AUTOSAR XML (schema 3.2.1)
package /TERootContainer
  8 x composition type:
    WindowTemperatureSystem
      provide port sense_frost: provided-interface=frost
      provide port sense_noFrost: provided-interface=noFrost
      component WindShieldTemperatureControl: type=WindShieldTemperatureControl
      component WindShieldtemperatureSensor: type=WindShieldtemperatureSensor
      connect WindShieldtemperatureSensor.sense_windShieldTemperature -> WindShieldTemperatureControl.sense_windShieldTemperature
      delegate WindShieldTemperatureControl.no_frost_detected <-> outer port sense_noFrost
      delegate WindShieldTemperatureControl.frost_detected <-> outer port sense_frost
    Power_Window
      8 x require port:
        PW_cls_unlock: required-interface=cls_unlock
        PW_cls_lock: required-interface=cls_lock
        PW_fp_off: required-interface=fp_off
        PW_pw_pos_dn: required-interface=pw_pos_dn
        PW_fp_on: required-interface=fp_on
        PW_pw_pos_up: required-interface=pw_pos_up
        PW_pw_but_up: required-interface=pw_but_up
        PW_pw_but_dn: required-interface=pw_but_dn
      5 x provide port:
        PW_pw_auto_mv_stop: provided-interface=pw_auto_mv_stop
        PW_pw_auto_mv_up: provided-interface=pw_auto_mv_up
        PW_pw_auto_mv_dn: provided-interface=pw_auto_mv_dn
        PW_pw_mv_dn: provided-interface=pw_mv_dn
        PW_pw_mv_up: provided-interface=pw_mv_up
      component ManPW: type=ManPW
      component AutoPW: type=AutoPW
      delegate AutoPW.pw_auto_mv_stop <-> outer port PW_pw_auto_mv_stop
      delegate AutoPW.pw_auto_mv_up <-> outer port PW_pw_auto_mv_up
      delegate AutoPW.pw_auto_mv_dn <-> outer port PW_pw_auto_mv_dn
      delegate ManPW.pw_mv_dn <-> outer port PW_pw_mv_dn
      delegate ManPW.pw_mv_up <-> outer port PW_pw_mv_up
      delegate AutoPW.AUtoPW_cls_unlock <-> outer port PW_cls_unlock
      delegate AutoPW.AutoPW_cls_lock <-> outer port PW_cls_lock
      delegate AutoPW.AutoPW_fp_off <-> outer port PW_fp_off
      delegate AutoPW.AutoPW_fp_on <-> outer port PW_fp_on
      delegate AutoPW.AutoPW_pw_but_dn <-> outer port PW_pw_pos_dn
      delegate AutoPW.AutpPW_pw_but_up <-> outer port PW_pw_pos_up
      delegate AutoPW.AutoPW_pw_pos_up <-> outer port PW_pw_but_up
      delegate AutoPW.AutoPW_pw_pos_dn <-> outer port PW_pw_but_dn
      delegate ManPW.ManPW_cls_unlock <-> outer port PW_cls_unlock
      delegate ManPW.ManPW_cls_lock <-> outer port PW_cls_lock
      delegate ManPW.ManPW_fp_off <-> outer port PW_fp_off
      delegate ManPW.ManPW_fp_on <-> outer port PW_fp_on
      delegate ManPW.ManPW_pw_but_dn <-> outer port PW_pw_pos_dn
      delegate ManPW.ManPW_pw_but_up <-> outer port PW_pw_pos_up
      delegate ManPW.ManPW_pw_pos_up <-> outer port PW_pw_but_up
      delegate ManPW.ManPW_pw_pos_dn <-> outer port PW_pw_but_dn
    WindowHeaterSystem
      require port sense_frost: required-interface=frost
      require port sense_noFrost: required-interface=noFrost
      component WindowHeatableController: type=WindowHeatableController
      component LED_HeatableWindow: type=LED_HeatableWindow
      component WindowHeater: type=WindowHeater
      connect WindowHeatableController.LED_HW_off -> LED_HeatableWindow.lED_HW_off
      connect WindowHeatableController.LED_HW_on -> LED_HeatableWindow.LED_HW_on
      connect WindowHeatableController.WH_off -> WindowHeater.Wh_off
      connect WindowHeatableController.Wh_on -> WindowHeater.WH_on
      delegate WindowHeatableController.sense_frost <-> outer port WindowHeaterSystem/sense_frost
      delegate WindowHeatableController.sense_noFrost <-> outer port WindowHeaterSystem/sense_noFrost
    ManPW
      8 x require port:
        ManPW_cls_unlock: required-interface=cls_unlock
        ManPW_cls_lock: required-interface=cls_lock
        ManPW_fp_off: required-interface=fp_off
        ManPW_fp_on: required-interface=fp_on
        ManPW_pw_pos_dn: required-interface=pw_but_dn
        ManPW_pw_pos_up: required-interface=pw_but_up
        ManPW_pw_but_up: required-interface=pw_pos_up
        ManPW_pw_but_dn: required-interface=pw_pos_dn
      provide port pw_mv_dn: provided-interface=pw_mv_dn
      provide port pw_mv_up: provided-interface=pw_mv_up
    AutomaticSeatadjustement
      require port rckc_keyID: required-interface=rckc_keyId
      9 x component:
        SeatPositioncontroller: type=SeatPositioncontroller
        WheelPosMotor: type=WheelPosMotor
        SeatForwardMotor: type=SeatForwardMotor
        SeatHeigthMotor: type=SeatHeigthMotor
        BackrestMotor: type=BackrestMotor
        WheelPosSensor: type=WheelPossensor
        SeatForwardPosSensor: type=SeatForwardPosSensor
        SeatHeigthSensor: type=SeatHeigthSensor
        BackrestPositionSensor: type=BackrestPositionSensor
      connect SeatPositioncontroller.mv_wheel_down -> WheelPosMotor.mv_wheel_down
      connect SeatPositioncontroller.mv_wheel_up -> WheelPosMotor.mv_wheel_up
      connect SeatPositioncontroller.mv_wheel_forward -> WheelPosMotor.mv_wheel_forward
      connect SeatPositioncontroller.mv_wheel_backward -> WheelPosMotor.mv_wheel_backward
      connect SeatPositioncontroller.mv_seat_backward -> SeatForwardMotor.mv_seat_backward
      connect SeatPositioncontroller.mv_seat_forward -> SeatForwardMotor.mv_seat_forward
      connect SeatPositioncontroller.mv_seat_down -> SeatHeigthMotor.mv_seat_down
      connect SeatPositioncontroller.mv_seat_up -> SeatHeigthMotor.mv_seat_up
      connect SeatPositioncontroller.mv_backrest_down -> BackrestMotor.mv_backrest_down
      connect SeatPositioncontroller.mv_backrest_up -> BackrestMotor.mv_backrest_up
      connect WheelPosSensor.wheelPos -> SeatPositioncontroller.wheelPos
      connect SeatForwardPosSensor.seatForwardPos -> SeatPositioncontroller.seatForwardPos
      connect SeatHeigthSensor.seatHeight -> SeatPositioncontroller.seatHeight
      connect BackrestPositionSensor.backrestPos -> SeatPositioncontroller.backrestPos
      delegate SeatPositioncontroller.rckc_keyID <-> outer port AutomaticSeatadjustement/rckc_keyID
    HL_System
      9 x require port:
        car_motor_off: required-interface=car_motor_off
        car_motor_on: required-interface=car_motor_on
        car_drives: required-interface=car_drives
        turn_HL_auto: required-interface=turn_HL_auto
        turn_HL_off: required-interface=turn_HL_off
        turn_HL_on: required-interface=turn_HL_on
        turn_HB_auto: required-interface=turn_HB_auto
        turn_HB_off: required-interface=turn_HB_off
        turn_HB_on: required-interface=turn_HB_on
      8 x component:
        HL_Controller: type=HL_Controller
        LightSensorController: type=LightSensorController
        HighBeam: type=HighBeam
        LowBeam: type=LowBeam
        DayTimeRunningLights: type=DayTimeRunningLights
        ParkingLights: type=ParkingLights
        ApproachingVehilceSensor: type=ApproachingVehilceSensor
        NatLightSensor: type=NatLightSensor
      connect HL_Controller.HB_off -> HighBeam.HB_off
      connect HL_Controller.HB_on -> HighBeam.HB_on
      connect HL_Controller.LB_off -> LowBeam.LB_off
      connect HL_Controller.LB_on -> LowBeam.LB_on
      connect HL_Controller.DRL_off -> DayTimeRunningLights.DRL_off
      connect HL_Controller.DRL_on -> DayTimeRunningLights.DRL_on
      connect HL_Controller.PL_off -> ParkingLights.PL_off
      connect HL_Controller.PL_on -> ParkingLights.PL_on
      connect HL_Controller.PL_on -> ParkingLights.PL_on
      connect LightSensorController.not_dark -> HL_Controller.not_dark
      connect LightSensorController.dark -> HL_Controller.dark
      connect NatLightSensor.LightingCondition -> LightSensorController.LightingCondition
      connect ApproachingVehilceSensor.AV_detected -> HL_Controller.AV_detected
      connect ApproachingVehilceSensor.no_AV_detected -> HL_Controller.no_AV_detected
      delegate HL_Controller.car_motor_on <-> outer port HL_System/car_motor_on
      delegate HL_Controller.car_motor_off <-> outer port HL_System/car_motor_off
      delegate HL_Controller.car_drives <-> outer port HL_System/car_drives
      delegate HL_Controller.turn_HL_auto <-> outer port HL_System/turn_HL_auto
      delegate HL_Controller.turn_HL_off <-> outer port HL_System/turn_HL_off
      delegate HL_Controller.turn_HL_on <-> outer port HL_System/turn_HL_on
      delegate HL_Controller.turn_HB_auto <-> outer port HL_System/turn_HB_auto
      delegate HL_Controller.turn_HB_off <-> outer port HL_System/turn_HB_off
      delegate HL_Controller.turn_HB_on <-> outer port HL_System/turn_HB_on
    WiperSystem
      10 x require port:
        sense_Frost: required-interface=frost
        sense_noFrost: required-interface=noFrost
        wip_func_auto_but: required-interface=wip_func_auto_but
        wip_func_clean_but: required-interface=wip_func_clean_but
        wip_func_disable_but: required-interface=wip_func_disable_but
        wip_func_perm_but: required-interface=wip_func_perm_but
        wip_func_enable_but: required-interface=wip_func_enable_but
        wip_speed_3_but: required-interface=wip_speed_l3_but
        wip_speed_l2_but: required-interface=wip_speed_l2_but
        wip_speed_l1_but: required-interface=wip_speed_l1_but
      6 x provide port:
        ledWiper_on: provided-interface=ledWiper_on
        ledWiper_off: provided-interface=ledWiper_off
        ledFrostProtecction_off: provided-interface=ledFrostProtection_off
        ledFrostPRotection_on: provided-interface=ledFrostProtection_on
        ledClean_off: provided-interface=ledClean_off
        ledClean_on: provided-interface=ledClean_on
      9 x component:
        ScreenWashController: type=ScreenWashController
        RainSensorController: type=RainSensorController
        WiperController: type=WiperController
        ScreenWashNozzle: type=ScreenWashNozzle
        HighQualityWiper: type=HighQualityWiper
        LowQualityWiper: type=LowQualityWiper
        HighQualityRainSensor: type=HighQualityRainSensor
        LowQualityRainSensor: type=LowQualityRainSensor
        ScreenWashSensor: type=ScreenWashSensor
      connect RainSensorController.rainSensor_WipeFast -> WiperController.rainSensor_WipeFast
      connect RainSensorController.rainSensor_WipeSlow -> WiperController.rainSensor_WipeSlow
      connect RainSensorController.rainSensor_WiperOff -> WiperController.rainSensor_WiperOff
      connect HighQualityRainSensor.sense_heavyRainDetected -> RainSensorController.sense_heavyRainDetected
      connect HighQualityRainSensor.sense_littleRainDetected -> RainSensorController.sense_littleRainDetected
      connect HighQualityRainSensor.sense_noRain -> RainSensorController.sense_noRain
      connect LowQualityRainSensor.sense_rainDetected -> RainSensorController.sense_rainDetected
      connect LowQualityRainSensor.sense_noRain -> RainSensorController.sense_noRain
      connect ScreenWashController.screenWashRefilled -> WiperController.screenWashRefilled
      connect ScreenWashController.screenWashLow -> WiperController.screenWashLow
      connect ScreenWashController.useScreenWash -> WiperController.useScreenWash_1
      connect ScreenWashSensor.sense_screenWashFill -> ScreenWashController.sense_screenWashFill
      connect WiperController.useScreenWash -> ScreenWashNozzle.useScreenWash
      connect WiperController.wipe_fast_speed -> HighQualityWiper.wipe_fast
      connect WiperController.wipe_medium_speed -> HighQualityWiper.wipe_medium
      connect WiperController.wipe_slow_speed -> HighQualityWiper.wipe_slow
      connect WiperController.wipe_clean -> HighQualityWiper.wipe_clean
      connect WiperController.wipe_clean -> LowQualityWiper.wipe_clean
      connect WiperController.wipe_slow_speed -> LowQualityWiper.wipe_slow
      delegate WiperController.autoWiping_off <-> outer port ledWiper_off
      delegate WiperController.autoWiping_on <-> outer port ledWiper_on
      delegate WiperController.ledFrostProtection_off <-> outer port ledFrostProtecction_off
      delegate WiperController.ledFrostProtection_on <-> outer port ledFrostPRotection_on
      delegate WiperController.ledClean_off <-> outer port WiperSystem/ledClean_off
      delegate WiperController.ledClean_on <-> outer port WiperSystem/ledClean_on
      delegate WiperController.wip_speed_l3_but <-> outer port wip_speed_3_but
      delegate WiperController.wip_speed_l2_but <-> outer port WiperSystem/wip_speed_l2_but
      delegate WiperController.frost_detected <-> outer port sense_Frost
      delegate WiperController.no_frost_detected <-> outer port WiperSystem/sense_noFrost
      delegate WiperController.wip_func_auto_but <-> outer port WiperSystem/wip_func_auto_but
      delegate ScreenWashController.wip_func_clean_but <-> outer port WiperSystem/wip_func_clean_but
      delegate WiperController.wip_func_enable_but <-> outer port WiperSystem/wip_func_enable_but
      delegate WiperController.wip_speed_l1_but <-> outer port WiperSystem/wip_speed_l1_but
    System_Software_Architecture  # System Software Architecture
      63 x component:
        HL_System: type=HL_System
        WindowHeaterSystem: type=WindowHeaterSystem
        WindowTemperatureSystem: type=WindowTemperatureSystem
        AutomaticSeatadjustement: type=AutomaticSeatadjustement
        WiperSystem: type=WiperSystem
        Power_Window: type=Power_Window
        LED_AlarmSystemInteriorMonit: type=LED_AlarmSystemInteriorMonit  # LED_AlarmSystemInteriorMonitoring
        LED_AlarmSystemAlarm: type=LED_AlarmSystemAlarm
        LED_AlarmSystemAlarmDetected: type=LED_AlarmSystemAlarmDetected
        LED_AlaramSystemActive: type=LED_AlaramSystemActive
        LED_CentralLockingSystem: type=LED_CentralLockingSystem
        LED_FingerProtection: type=LED_FingerProtection
        LED_ExteriorMirrorHeating: type=LED_ExteriorMirrorHeating
        LED_ExteriorMirrorBottom: type=LED_ExteriorMirrorBottom
        LED_ExteriorMirrorRight: type=LED_ExteriorMirrorRight
        LED_ExteriorMirrorLeft: type=LED_ExteriorMirrorLeft
        LED_ExteriorMirrorTop: type=LED_ExteriorMirrorTop
        LED_AutomaticPowerWindow: type=LED_AutomaticPowerWindow
        LED_ManualPowerWindow: type=LED_ManualPowerWindow
        HumanMachineInterface: type=HumanMachineInterface
        CentralLockingSystem: type=CentralLockingSystem
        RemoteControlKeyController: type=RemoteControlKeyController
        AlarmSystem: type=AlarmSystem
        FingerProtection: type=FingerProtection
        ExteriorMirror: type=ExteriorMirror
        HeadLightSwitch: type=HeadLightSwitch
        HighBeamSwitch: type=HighBeamSwitch
        LEDFrostProtection: type=LEDFrostProtection
        LEDClean: type=LEDClean
        LEDWiper: type=LEDWiper
        Wip_Speed_Panel: type=Wip_Speed_Panel
        Wip_Function_Panel: type=Wip_Function_Panel
        PW_Remote_Control: type=PW_Remote_Control
        Remote_Cotroll_Key: type=Remote_Cotroll_Key
        PW_Button_DN: type=PW_Button_DN
        PW_Button_UP: type=PW_Button_UP
        Alarm_System_Control: type=Alarm_System_Control
        EM_Button: type=EM_Button
        Alarm_Sensor: type=Alarm_Sensor
        LED_ASIM: type=LED_ASIM
        LED_ASAC: type=LED_ASAC
        LED_ASA: type=LED_ASA
        LED_ASAD: type=LED_ASAD
        LED_PW_CLS_UP: type=LED_PW_CLS_UP
        LED_PW_down: type=LED_PW_down
        LED_PW_UP: type=LED_PW_UP
        LED_Heating: type=LED_Heating
        LED_EM_Left: type=LED_EM_Left
        LED_EM_Right: type=LED_EM_Right
        LED_EM_Top: type=LED_EM_Top
        LED_EM_Bottom: type=LED_EM_Bottom
        EM_Motor: type=EM_Motor
        LED_FP: type=LED_FP
        Heating_timer: type=Heating_timer
        Thermometer: type=Thermometer
        EM_Pos_Sensor: type=EM_Pos_Sensor
        Finger_Sensor_SWA: type=Finger_Sensor_SWA
        PW_pos_Sensor: type=PW_pos_Sensor
        Car_locking_system: type=Car_locking_system
        door_sensor: type=door_sensor
        driving_sensor: type=driving_sensor
        Key_Pos_Sensor: type=Key_Pos_Sensor
        CLS_LED: type=CLS_LED
      connect .sense_frost -> .sense_frost  # Assembly Connector286
      connect .sense_frost -> .sense_Frost  # Assembly Connector285
      connect .sense_noFrost -> .sense_noFrost  # Assembly Connector284
      connect .sense_noFrost -> .sense_noFrost  # Assembly Connector283
      connect .ledWiper_off -> LEDWiper.ledWiper_off  # Assembly Connector234
      connect .ledWiper_on -> LEDWiper.ledWiper_on  # Assembly Connector233
      connect .ledFrostProtecction_off -> LEDFrostProtection.ledFrostProtection_off  # Assembly Connector232
      connect .ledFrostPRotection_on -> LEDFrostProtection.ledFrostProtection_on  # Assembly Connector231
      connect .ledClean_off -> LEDClean.ledClean_off  # Assembly Connector230
      connect .ledClean_on -> LEDClean.ledClean_on  # Assembly Connector229
      connect .PW_pw_mv_dn -> LED_ManualPowerWindow.pw_mv_dn
      connect .PW_pw_mv_up -> LED_ManualPowerWindow.pw_mv_up
      connect .PW_pw_auto_mv_dn -> LED_AutomaticPowerWindow.pw_auto_mv_dn  # PW_to_LED_AutoPW_pw_auto_mv_dn
      connect .PW_pw_auto_mv_up -> LED_AutomaticPowerWindow.pw_auto_mv_up  # PW_to_LED_AutpPW_pw_auto_mv_up
      connect .PW_pw_auto_mv_stop -> LED_AutomaticPowerWindow.pw_auto_mv_stop  # PW_to_LED_AutpPW_pw_auto_mv_stop
      connect driving_sensor.car_drives -> .car_drives  # Assembly Connector367
      connect driving_sensor.car_motor_off -> .car_motor_off  # Assembly Connector366
      connect driving_sensor.car_motor_on -> .car_motor_on  # Assembly Connector365
      connect HumanMachineInterface.turn_HL_auto -> .turn_HL_auto  # Assembly Connector364
      connect HumanMachineInterface.turn_HL_off -> .turn_HL_off  # Assembly Connector363
      connect HumanMachineInterface.turn_HL_on -> .turn_HL_on  # Assembly Connector362
      connect HumanMachineInterface.turn_HB_auto -> .turn_HB_auto  # Assembly Connector361
      connect HumanMachineInterface.turn_HB_off -> .turn_HB_off  # Assembly Connector360
      connect HumanMachineInterface.turn_HB_on -> .turn_HB_on  # Assembly Connector359
      connect RemoteControlKeyController.rckc_keyId -> .rckc_keyID  # Assembly Connector252
      connect HumanMachineInterface.wip_func_auto_but -> .wip_func_auto_but  # Assembly Connector242
      connect HumanMachineInterface.wip_func_disable_but -> .wip_func_disable_but  # Assembly Connector241
      connect HumanMachineInterface.wip_func_perm_but -> .wip_func_perm_but  # Assembly Connector240
      connect HumanMachineInterface.wip_func_enable_but -> .wip_func_enable_but  # Assembly Connector239
      connect HumanMachineInterface.wip_func_clean_but -> .wip_func_clean_but  # Assembly Connector238
      connect HumanMachineInterface.wip_speed_l3_but -> .wip_speed_3_but  # Assembly Connector237
      connect HumanMachineInterface.wip_speed_l2_but -> .wip_speed_l2_but  # Assembly Connector236
      connect HumanMachineInterface.wip_speed_l1_but -> .wip_speed_l1_but  # Assembly Connector235
      connect PW_pos_Sensor.pw_pos_dn -> .PW_pw_pos_dn
      connect PW_pos_Sensor.pw_pos_up -> .PW_pw_pos_up
      connect HumanMachineInterface.pw_but_up -> .PW_pw_but_up
      connect FingerProtection.fp_off -> .PW_fp_off
      connect FingerProtection.fp_on -> .PW_fp_on
      connect CentralLockingSystem.cls_unlock -> .PW_cls_unlock
      connect CentralLockingSystem.cls_lock -> .PW_cls_lock
      connect RemoteControlKeyController.pw_but_dn -> .PW_pw_but_dn
      connect RemoteControlKeyController.pw_but_up -> .PW_pw_but_up
      connect HumanMachineInterface.pw_but_dn -> .PW_pw_but_dn
      connect HeadLightSwitch.HL_auto_but -> HumanMachineInterface.HL_auto_but  # Assembly Connector358
      connect HeadLightSwitch.HL_off_but -> HumanMachineInterface.HL_on_but  # Assembly Connector357
      connect HeadLightSwitch.HL_on_but -> HumanMachineInterface.HL_off_but  # Assembly Connector356
      connect HighBeamSwitch.HB_auto_but -> HumanMachineInterface.HB_auto_but  # Assembly Connector355
      connect HighBeamSwitch.HB_on_but -> HumanMachineInterface.HB_on_but  # Assembly Connector354
      connect HighBeamSwitch.HB_off_but -> HumanMachineInterface.HB_off_but  # Assembly Connector353
      connect Remote_Cotroll_Key.rck_keyId -> RemoteControlKeyController.rck_keyID  # Assembly Connector251
      connect Wip_Function_Panel.wip_auto_but -> HumanMachineInterface.wip_auto_but  # Assembly Connector250
      connect Wip_Function_Panel.wip_clean_but -> HumanMachineInterface.wip_clean_but  # Assembly Connector249
      connect Wip_Function_Panel.wip_perm_but -> HumanMachineInterface.wip_perm_but  # Assembly Connector248
      connect Wip_Function_Panel.wip_disable_but -> HumanMachineInterface.wip_disable_but  # Assembly Connector247
      connect Wip_Function_Panel.wip_enable_but -> HumanMachineInterface.wip_enable_but  # Assembly Connector246
      connect Wip_Speed_Panel.wip_l3_but -> HumanMachineInterface.wip_l3_but  # Assembly Connector245
      connect Wip_Speed_Panel.wip_l2_but -> HumanMachineInterface.wip_l2_but  # Assembly Connector244
      connect Wip_Speed_Panel.wip_l1_but -> HumanMachineInterface.wip_l1_but  # Assembly Connector243
      connect Key_Pos_Sensor.key_pos_unlock -> AlarmSystem.key_pos_unlock  # Key_Pos_Sensor_to_AS_key_pos_unlock
      connect Key_Pos_Sensor.key_pos_lock -> AlarmSystem.key_pos_lock  # Key_pos_Sensor_to_AS_key_pos_lock
      connect RemoteControlKeyController.rck_unlock -> AlarmSystem.rck_unlock
      connect RemoteControlKeyController.rck_lock -> AlarmSystem.rck_lock
      connect RemoteControlKeyController.rck_unlock -> CentralLockingSystem.rck_unlock
      connect RemoteControlKeyController.rck_lock -> CentralLockingSystem.rck_lock
      connect door_sensor.door_open -> CentralLockingSystem.door_open
      connect door_sensor.door_open -> RemoteControlKeyController.door_open  # Door_Sensor_to_RCKC_door_open
      connect LED_AlarmSystemInteriorMonit.led_as_im_alarm_off -> LED_ASIM.led_off
      connect LED_AlarmSystemInteriorMonit.led_as_im_alarm_on -> LED_ASIM.led_on
      connect LED_AlaramSystemActive.led_as_active_off -> LED_ASAC.led_off
      connect LED_AlaramSystemActive.led_as_active_on -> LED_ASAC.led_on
      connect LED_AlarmSystemAlarm.led_as_alarm_off -> LED_ASA.led_off
      connect LED_AlarmSystemAlarm.led_as_alarm_on -> LED_ASA.led_on
      connect LED_AlarmSystemAlarmDetected.led_as_alarm_detected_off -> LED_ASAD.led_off
      connect LED_AlarmSystemAlarmDetected.led_as_alarm_detected_on -> LED_ASAD.led_on
      connect LED_AutomaticPowerWindow.led_pw_dn_off -> LED_PW_down.led_off  # LED_AUTOPW_to_LED_PW_down_off
      connect LED_AutomaticPowerWindow.led_pw_dn_on -> LED_PW_down.led_on
      connect LED_ManualPowerWindow.led_pw_dn_on -> LED_PW_down.led_on
      connect LED_AutomaticPowerWindow.led_pw_cls_up_on -> LED_PW_CLS_UP.led_on  # LED_AUTOPW_to_LED_PW_CLS_UP_on
      connect LED_AutomaticPowerWindow.led_pw_cls_up_off -> LED_PW_CLS_UP.led_off  # LED_AUTOPW_to_LED_PW_CLS_UP_off
      connect LED_ManualPowerWindow.led_pw_dn_off -> LED_PW_down.led_off
      connect LED_ManualPowerWindow.led_pw_up_off -> LED_PW_UP.led_off
      connect LED_ManualPowerWindow.led_pw_up_on -> LED_PW_UP.led_on
      connect LED_AutomaticPowerWindow.led_pw_up_off -> LED_PW_UP.led_off
      connect LED_AutomaticPowerWindow.led_pw_up_on -> LED_PW_UP.led_on
      connect LED_ExteriorMirrorHeating.led_em_heating_off -> LED_Heating.led_off  # LED_EM_Heating_to_LED_Heating_off
      connect LED_ExteriorMirrorHeating.led_em_heating_on -> LED_Heating.led_on  # LED_EM_Heating_to_LED_Heating_on
      connect LED_ExteriorMirrorLeft.led_em_left_off -> LED_EM_Left.led_off  # LED_EM_Left_to_LED_EM_Left_off
      connect LED_ExteriorMirrorLeft.led_em_left_on -> LED_EM_Left.led_on  # LED_EM_Left_to_LED_EM_Left_on
      connect LED_ExteriorMirrorRight.led_em_right_off -> LED_EM_Right.led_off  # LED_EM_Right_to_LED_EM_Right_off
      connect LED_ExteriorMirrorRight.led_em_right_on -> LED_EM_Right.led_on  # LED_EM_Right_to_LED_EM_Right_on
      connect LED_ExteriorMirrorTop.led_em_top_off -> LED_EM_Top.led_off
      connect LED_ExteriorMirrorTop.led_em_top_on -> LED_EM_Top.led_on
      connect LED_ExteriorMirrorBottom.led_em_bottom_off -> LED_EM_Bottom.led_off  # LED_EM_Bottom_to_LED_EM_Bottom_off
      connect LED_ExteriorMirrorBottom.led_em_bottom_on -> LED_EM_Bottom.led_on  # LED_EM_Bottom_to_LED_EM_Bottom_on
      connect LED_FingerProtection.led_fp_off -> LED_FP.led_fp_off  # LED_Fingerprotection_to_LED_FP_off
      connect LED_FingerProtection.led_fp_on -> LED_FP.led_fp_on  # LED_Fingerprotection_to_LED_FP_on
      connect Finger_Sensor_SWA.finger_detected -> FingerProtection.finger_detected  # Finger_Snesor_to_FP_finger_detected
      connect ExteriorMirror.em_mv_down -> EM_Motor.em_mv_down
      connect ExteriorMirror.em_mv_up -> EM_Motor.em_mv_up
      connect ExteriorMirror.em_mv_right -> EM_Motor.em_mv_right
      connect ExteriorMirror.em_mv_left -> EM_Motor.em_mv_left
      connect Heating_timer.heating_time_elapsed -> ExteriorMirror.time_heating_elapsed  # Heating_Timer_to_EM_heating_time_elapsed
      connect Thermometer.em_too_cold -> ExteriorMirror.em_too_cold
      connect EM_Pos_Sensor.em_pos_top -> ExteriorMirror.em_pos_top
      connect EM_Pos_Sensor.em_pos_bottom -> ExteriorMirror.em_pos_bottom  # EM_Pos_Sensor_to_EM_pos_bottom
      connect EM_Pos_Sensor.em_pos_right -> ExteriorMirror.em_pos_right  # EM_Pos_Sensor_to_EM_pos_right
      connect EM_Pos_Sensor.em_pos_left -> ExteriorMirror.em_pos_left
      connect Alarm_Sensor.im_alarm_detected -> AlarmSystem.im_alarm_detected  # Alarm_Sensor_to_Alarm_System_im_alarm_detected
      connect Alarm_Sensor.alarm_detected -> AlarmSystem.as_alarm_detected  # Alarm_Sensor_to_Alarm_System_alarm_detected
      connect Alarm_Sensor.alarm_time_elapsed -> AlarmSystem.time_alarm_elapsed  # Alarm_Sensor_to_Alarm_System_time_alarm_elapsed
      connect Key_Pos_Sensor.key_pos_unlock -> CentralLockingSystem.key_pos_unlock
      connect Key_Pos_Sensor.key_pos_lock -> CentralLockingSystem.key_pos_lock
      connect driving_sensor.car_drives -> CentralLockingSystem.car_drives  # Drinving_Sensor_to_CLS_car_drives
      connect PW_Remote_Control.pw_but_down -> RemoteControlKeyController.pw_rm_dn
      connect PW_Remote_Control.pw_but_up -> RemoteControlKeyController.pw_rm_up
      connect Remote_Cotroll_Key.rck_timer -> RemoteControlKeyController.time_rck_sf_elapsed
      connect Remote_Cotroll_Key.rck_but_unlock -> RemoteControlKeyController.rck_but_unlock
      connect Remote_Cotroll_Key.rck_but_lock -> RemoteControlKeyController.rck_but_lock
      connect PW_Button_DN.pw_but_released -> HumanMachineInterface.release_pw_but_dn
      connect PW_Button_DN.pw_but_pressed -> HumanMachineInterface.pw_but_mv_dn
      connect PW_Button_UP.pw_but_released -> HumanMachineInterface.release_pw_but_up
      connect PW_Button_UP.pw_but_pressed -> HumanMachineInterface.pw_but_mv_up
      connect Alarm_System_Control.confirm_alarm -> HumanMachineInterface.confirm_alarm
      connect Alarm_System_Control.deactivate_as -> HumanMachineInterface.deactivate_as
      connect Alarm_System_Control.activate_as -> HumanMachineInterface.activate_as
      connect EM_Button.em_but_mv_dn -> HumanMachineInterface.em_but_mv_dn
      connect EM_Button.em_but_mv_up -> HumanMachineInterface.em_but_mv_up
      connect EM_Button.em_but_mv_right -> HumanMachineInterface.em_but_mv_right  # EM_Button_to_HMI_but_mv_right
      connect EM_Button.em_but_mv_left -> HumanMachineInterface.em_but_mv_left
      connect CentralLockingSystem.car_unlock -> Car_locking_system.car_unlock
      connect CentralLockingSystem.car_lock -> Car_locking_system.car_lock
      connect LED_CentralLockingSystem.led_cls_off -> CLS_LED.led_cls_off
      connect LED_CentralLockingSystem.led_cls_on -> CLS_LED.led_cls_on
      connect ExteriorMirror.heating_on -> LED_ExteriorMirrorHeating.heating_on
      connect ExteriorMirror.heating_off -> LED_ExteriorMirrorHeating.heating_off
      connect ExteriorMirror.em_pos_hor_left -> LED_ExteriorMirrorLeft.em_pos_hor_left  # EM_to_LED_EML_em_pos_hor_left
      connect ExteriorMirror.em_pos_hor_pend -> LED_ExteriorMirrorLeft.em_pos_hor_pend  # EM_to_LED_EML_em_pos_hor_pend
      connect ExteriorMirror.em_pos_hor_pend -> LED_ExteriorMirrorRight.em_pos_hor_pend  # EM_to_LED_EMR_em_pos_hor_pend
      connect ExteriorMirror.em_pos_hor_right -> LED_ExteriorMirrorRight.em_pos_hor_right  # EM_to_LED_EMR_em_pos_hor_right
      connect ExteriorMirror.em_pos_vert_top -> LED_ExteriorMirrorTop.em_pos_vert_top  # EM_to_LED_EMT_em_pos_vert_top
      connect ExteriorMirror.em_pos_vert_pend -> LED_ExteriorMirrorTop.em_pos_vert_pend  # EM_to_LED_EMT_em_pos_vert_pend
      connect ExteriorMirror.em_pos_vert_pend -> LED_ExteriorMirrorBottom.em_pos_vert_pend  # EM_to_LED_EMB_em_pos_vert_pend
      connect ExteriorMirror.em_pos_vert_bottom -> LED_ExteriorMirrorBottom.em_pos_vert_bottom  # EM_to_LED_EMB_em_pos_vert_bottom
      connect HumanMachineInterface.release_pw_but -> LED_ManualPowerWindow.release_pw_but  # HMI_to_LED_ManPW_release_pw_but
      connect AlarmSystem.as_im_alarm_off -> LED_AlarmSystemInteriorMonit.as_im_alarm_off  # AS_to_LED_ASIM_as_im_alarm_off
      connect AlarmSystem.as_im_alarm_on -> LED_AlarmSystemInteriorMonit.as_im_alarm_on  # AS_to_LED_ASIM_as_im_alarm_on
      connect AlarmSystem.as_active_off -> LED_AlaramSystemActive.as_active_off
      connect AlarmSystem.as_active_on -> LED_AlaramSystemActive.as_active_on
      connect CentralLockingSystem.cls_lock -> LED_AutomaticPowerWindow.cls_lock
      connect CentralLockingSystem.cls_unlock -> LED_AutomaticPowerWindow.cls_unlock
      connect AlarmSystem.as_alarm_off -> LED_AlarmSystemAlarm.as_alarm_off
      connect AlarmSystem.as_alarm_on -> LED_AlarmSystemAlarm.as_alarm_on
      connect AlarmSystem.as_alarm_was_detected -> LED_AlarmSystemAlarmDetected.as_alarm_was_detected  # AS_to_LED_ASAD_as_alarm_was_detected
      connect HumanMachineInterface.as_alarm_was_confirmed -> LED_AlarmSystemAlarmDetected.as_alarm_was_confirmed  # HMI_LED_ASAD_alram_was_confirmed
      connect FingerProtection.fp_off -> LED_FingerProtection.fp_off
      connect FingerProtection.fp_on -> LED_FingerProtection.fp_on
      connect HumanMachineInterface.as_activated -> AlarmSystem.as_activated
      connect HumanMachineInterface.as_deactivated -> AlarmSystem.as_deactivated
      connect CentralLockingSystem.cls_lock -> LED_CentralLockingSystem.cls_lock
      connect CentralLockingSystem.cls_unlock -> LED_CentralLockingSystem.cls_unlock
      connect HumanMachineInterface.pw_but_dn -> FingerProtection.pw_but_dn
      connect HumanMachineInterface.em_but_left -> ExteriorMirror.em_but_left
      connect HumanMachineInterface.em_but_up -> ExteriorMirror.em_but_up
      connect HumanMachineInterface.em_but_dn -> ExteriorMirror.em_but_down
      connect HumanMachineInterface.em_but_right -> ExteriorMirror.em_but_right
package /SystemInformation
  system System_System_Software_Architecture:
    fibex-element=[HL_Controller, WindowHeatableController, WindowTemperatureController, SeatAdjustement, ECU5_Wiper, ECU2_HMI, ECU1_Doorsystem, CLS_ECU4, Alarm_System_ECU3, HighBeam, LowBeam, DaytimeRunningLights, ParkingLights, LED_HeatableWindow, WindowHeater, WheelPosMotor, SeatForwardMotor, SeatHeightMotor, BackrestMotor, ScreenWashNozzle, LowQualityWiper, LED_Wiper, LED_Clean, LED_PW_Up, LED_PW_DN, LED_PW_CLS, LED_Frost, LED_FP, LED_EMT, LED_EMR, LED_EML, LED_EMB, LED_EM_Heating, LED_CLS, LED_ASIM, LED_ASAL, LED_ASAD, LED_ASAC, HighQualityWiper, EM_Motor, Car_Locking_System, ApproachingVehicle_snesor, NatLight_sensor, HeadLightSwitch, HighBeamSwitch, WindShieldTemperatureSensor, WheelPositionSensor, SeatForwardSensor, SeatHeightSensor, BackrestPositionSensor, Wiper_Speed_But, Wiper_Function_But, ScreenWashSensor, LowQualityRainSensor, HighQualityRainSensor, Thermoeter, Remote_Control_Key, RCK_PW_Buttons, PW_Position_Sensor, PW_But_UP, PW_But_DN, Key_Pos_Sensor, Heating_Timer, Finger_Sensor_HW, EM_Pos_Sensor, EM_Button, Driving_Snesor, Door_Sensor, Alarm_System_Control, Alarm_Sensor]
    pnc-vector-length=0
    pnc-vector-offset=0
    mapping Mapping
      sw-impl-mappings:
        28 x swc to impl mapping:
          swcMapping_LED_FingerProtect: component-implementation=Impl_LED_FingerProtection, component=System_Software_Architecture.LED_FingerProtection
          swcMapping_ExteriorMirror: component-implementation=Impl_ExteriorMirror, component=System_Software_Architecture.ExteriorMirror
          swcMapping_LED_ExteriorMirro_4: component-implementation=Impl_LED_ExteriorMirrorTop, component=System_Software_Architecture.LED_ExteriorMirrorTop
          swcMapping_LED_ExteriorMirro: component-implementation=Impl_LED_ExteriorMirrorHeati, component=System_Software_Architecture.LED_ExteriorMirrorHeating
          swcMapping_LED_CentralLockin: component-implementation=Impl_LED_CentralLockingSyste, component=System_Software_Architecture.LED_CentralLockingSystem
          swcMapping_LED_AlaramSystemA: component-implementation=Impl_LED_AlaramSystemActive, component=System_Software_Architecture.LED_AlaramSystemActive
          swcMapping_LightSensorContro: component-implementation=Impl_LightSensorController, component=System_Software_Architecture.HL_System.LightSensorController
          swcMapping_ScreenWashControl: component-implementation=Impl_ScreenWashController, component=System_Software_Architecture.WiperSystem.ScreenWashController
          swcMapping_WindowHeatableCon: component-implementation=Impl_WindowHeatableControlle, component=System_Software_Architecture.WindowHeaterSystem.WindowHeatableController
          swcMapping_HumanMachineInter: component-implementation=Impl_HumanMachineInterface, component=System_Software_Architecture.HumanMachineInterface
          swcMapping_LED_ExteriorMirro_3: component-implementation=Impl_LED_ExteriorMirrorLeft, component=System_Software_Architecture.LED_ExteriorMirrorLeft
          swcMapping_RemoteControlKeyC: component-implementation=Impl_RemoteControlKeyControl, component=System_Software_Architecture.RemoteControlKeyController
          swcMapping_RainSensorControl: component-implementation=Impl_RainSensorController, component=System_Software_Architecture.WiperSystem.RainSensorController
          swcMapping_LED_AlarmSystemAl_1: component-implementation=Impl_LED_AlarmSystemAlarmDet, component=System_Software_Architecture.LED_AlarmSystemAlarmDetected
          swcMapping_LED_AutomaticPowe: component-implementation=Impl_LED_AutomaticPowerWindo, component=System_Software_Architecture.LED_AutomaticPowerWindow
          swcMapping_CentralLockingSys: component-implementation=Impl_CentralLockingSystem, component=System_Software_Architecture.CentralLockingSystem
          swcMapping_WiperController: component-implementation=Impl_WiperController, component=System_Software_Architecture.WiperSystem.WiperController
          swcMapping_AutoPW: component-implementation=Impl_AutoPW, component=System_Software_Architecture.Power_Window.AutoPW
          swcMapping_AlarmSystem: component-implementation=Impl_AlarmSystem, component=System_Software_Architecture.AlarmSystem
          swcMapping_LED_ExteriorMirro_2: component-implementation=Impl_LED_ExteriorMirrorRight, component=System_Software_Architecture.LED_ExteriorMirrorRight
          swcMapping_LED_ExteriorMirro_1: component-implementation=Impl_LED_ExteriorMirrorBotto, component=System_Software_Architecture.LED_ExteriorMirrorBottom
          swcMapping_WindShieldTempera: component-implementation=Impl_WindShieldTemperatureCo, component=System_Software_Architecture.WindowTemperatureSystem.WindShieldTemperatureControl
          swcMapping_SeatPositioncontr: component-implementation=Impl_SeatPositioncontroller, component=System_Software_Architecture.AutomaticSeatadjustement.SeatPositioncontroller
          swcMapping_LED_AlarmSystemAl: component-implementation=Impl_LED_AlarmSystemAlarm, component=System_Software_Architecture.LED_AlarmSystemAlarm
          swcMapping_FingerProtection: component-implementation=Impl_FingerProtection, component=System_Software_Architecture.FingerProtection
          swcMapping_LED_ManualPowerWi: component-implementation=Impl_LED_ManualPowerWindow, component=System_Software_Architecture.LED_ManualPowerWindow
          swcMapping_LED_AlarmSystemIn: component-implementation=Impl_LED_AlarmSystemInterior, component=System_Software_Architecture.LED_AlarmSystemInteriorMonit
          swcMapping_HL_Controller: component-implementation=Impl_HL_Controller, component=System_Software_Architecture.HL_System.HL_Controller
      sw-mappings:
        68 x swc to ecu mapping:
          SeatHeightMotor_FBMapping: component=System_Software_Architecture.AutomaticSeatadjustement.SeatHeigthMotor, ecu-instance=SeatHeightMotor
          ECU5_Wiper_FBMapping: ecu-instance=ECU5_Wiper
            component:
              System_Software_Architecture.WiperSystem.ScreenWashController
              System_Software_Architecture.WiperSystem.WiperController
              System_Software_Architecture.WiperSystem.RainSensorController
          LED_HeatableWindow_FBMapping: component=System_Software_Architecture.WindowHeaterSystem.LED_HeatableWindow, ecu-instance=LED_HeatableWindow
          ApproachingVehicle_snesor_FB: component=System_Software_Architecture.HL_System.ApproachingVehilceSensor, ecu-instance=ApproachingVehicle_snesor
          HighQualityWiper_FBMapping: component=System_Software_Architecture.WiperSystem.HighQualityWiper, ecu-instance=HighQualityWiper
          RCK_PW_Buttons_FBMapping: component=System_Software_Architecture.PW_Remote_Control, ecu-instance=RCK_PW_Buttons
          CLS_ECU4_FBMapping: ecu-instance=CLS_ECU4
            component:
              System_Software_Architecture.RemoteControlKeyController
              System_Software_Architecture.CentralLockingSystem
          ECU1_Doorsystem_FBMapping: ecu-instance=ECU1_Doorsystem
            component:
              System_Software_Architecture.Power_Window.AutoPW
              System_Software_Architecture.ExteriorMirror
              System_Software_Architecture.FingerProtection
              System_Software_Architecture.Power_Window.ManPW
          ECU2_HMI_FBMapping: ecu-instance=ECU2_HMI
            component:
              System_Software_Architecture.LED_ExteriorMirrorTop
              System_Software_Architecture.LED_AlarmSystemAlarm
              System_Software_Architecture.HumanMachineInterface
              System_Software_Architecture.LED_ExteriorMirrorBottom
              System_Software_Architecture.LED_AlaramSystemActive
              System_Software_Architecture.LED_ExteriorMirrorLeft
              System_Software_Architecture.LED_ExteriorMirrorHeating
              System_Software_Architecture.LED_ManualPowerWindow
              System_Software_Architecture.LED_CentralLockingSystem
              System_Software_Architecture.LED_AlarmSystemAlarmDetected
              System_Software_Architecture.LED_ExteriorMirrorRight
              System_Software_Architecture.LED_AlarmSystemInteriorMonit
              System_Software_Architecture.LED_FingerProtection
              System_Software_Architecture.LED_AutomaticPowerWindow
          EM_Pos_Sensor_FBMapping: component=System_Software_Architecture.EM_Pos_Sensor, ecu-instance=EM_Pos_Sensor
          LED_ASIM_FBMapping: component=System_Software_Architecture.LED_ASIM, ecu-instance=LED_ASIM
          ScreenWashSensor_FBMapping: ecu-instance=ScreenWashSensor
            component:
              System_Software_Architecture.WiperSystem.ScreenWashSensor
              System_Software_Architecture.WiperSystem.ScreenWashNozzle
          BackrestPositionSensor_FBMap: component=System_Software_Architecture.AutomaticSeatadjustement.BackrestPositionSensor, ecu-instance=BackrestPositionSensor
          LED_EMR_FBMapping: component=System_Software_Architecture.LED_EM_Right, ecu-instance=LED_EMR
          EM_Motor_FBMapping: component=System_Software_Architecture.EM_Motor, ecu-instance=EM_Motor
          HL_Controller_FBMapping: ecu-instance=HL_Controller
            component:
              System_Software_Architecture.HL_System.LightSensorController
              System_Software_Architecture.HL_System.HL_Controller
          Remote_Control_Key_FBMapping: component=System_Software_Architecture.Remote_Cotroll_Key, ecu-instance=Remote_Control_Key
          LED_Wiper_FBMapping: component=System_Software_Architecture.LEDWiper, ecu-instance=LED_Wiper
          LowBeam_FBMapping: component=System_Software_Architecture.HL_System.LowBeam, ecu-instance=LowBeam
          LED_EMT_FBMapping: component=System_Software_Architecture.LED_EM_Top, ecu-instance=LED_EMT
          WindowTemperatureController_: component=System_Software_Architecture.WindowTemperatureSystem.WindShieldTemperatureControl, ecu-instance=WindowTemperatureController
          Key_Pos_Sensor_FBMapping: component=System_Software_Architecture.Key_Pos_Sensor, ecu-instance=Key_Pos_Sensor
          HighQualityRainSensor_FBMapp: component=System_Software_Architecture.WiperSystem.HighQualityRainSensor, ecu-instance=HighQualityRainSensor
          Heating_Timer_FBMapping: component=System_Software_Architecture.Heating_timer, ecu-instance=Heating_Timer
          SeatForwardMotor_FBMapping: component=System_Software_Architecture.AutomaticSeatadjustement.SeatForwardMotor, ecu-instance=SeatForwardMotor
          DaytimeRunningLights_FBMappi: component=System_Software_Architecture.HL_System.DayTimeRunningLights, ecu-instance=DaytimeRunningLights
          Driving_Snesor_FBMapping: component=System_Software_Architecture.driving_sensor, ecu-instance=Driving_Snesor
          ParkingLights_FBMapping: component=System_Software_Architecture.HL_System.ParkingLights, ecu-instance=ParkingLights
          PW_But_DN_FBMapping: component=System_Software_Architecture.PW_Button_DN, ecu-instance=PW_But_DN
          SeatAdjustement_FBMapping: component=System_Software_Architecture.AutomaticSeatadjustement.SeatPositioncontroller, ecu-instance=SeatAdjustement
          LED_CLS_FBMapping: component=[System_Software_Architecture.LED_PW_CLS_UP, System_Software_Architecture.CLS_LED], ecu-instance=LED_CLS
          LED_FP_FBMapping: component=System_Software_Architecture.LED_FP, ecu-instance=LED_FP
          Door_Sensor_FBMapping: component=System_Software_Architecture.door_sensor, ecu-instance=Door_Sensor
          BackrestMotor_FBMapping: component=System_Software_Architecture.AutomaticSeatadjustement.BackrestMotor, ecu-instance=BackrestMotor
          WheelPosMotor_FBMapping: component=System_Software_Architecture.AutomaticSeatadjustement.WheelPosMotor, ecu-instance=WheelPosMotor
          LowQualityRainSensor_FBMappi: component=System_Software_Architecture.WiperSystem.LowQualityRainSensor, ecu-instance=LowQualityRainSensor
          LED_ASAC_FBMapping: component=System_Software_Architecture.LED_ASAC, ecu-instance=LED_ASAC
          PW_But_UP_FBMapping: component=System_Software_Architecture.PW_Button_UP, ecu-instance=PW_But_UP
          Alarm_System_ECU3_FBMapping: component=System_Software_Architecture.AlarmSystem, ecu-instance=Alarm_System_ECU3
          Finger_Sensor_HW_FBMapping: component=System_Software_Architecture.Finger_Sensor_SWA, ecu-instance=Finger_Sensor_HW
          WindowHeatableController_FBM: component=System_Software_Architecture.WindowHeaterSystem.WindowHeatableController, ecu-instance=WindowHeatableController
          LED_EMB_FBMapping: component=System_Software_Architecture.LED_EM_Bottom, ecu-instance=LED_EMB
          WindShieldTemperatureSensor_: component=System_Software_Architecture.WindowTemperatureSystem.WindShieldtemperatureSensor, ecu-instance=WindShieldTemperatureSensor
          Alarm_Sensor_FBMapping: component=System_Software_Architecture.Alarm_Sensor, ecu-instance=Alarm_Sensor
          NatLight_sensor_FBMapping: component=System_Software_Architecture.HL_System.NatLightSensor, ecu-instance=NatLight_sensor
          HighBeam_FBMapping: component=System_Software_Architecture.HL_System.HighBeam, ecu-instance=HighBeam
          SeatForwardSensor_FBMapping: component=System_Software_Architecture.AutomaticSeatadjustement.SeatForwardPosSensor, ecu-instance=SeatForwardSensor
          LowQualityWiper_FBMapping: component=System_Software_Architecture.WiperSystem.LowQualityWiper, ecu-instance=LowQualityWiper
          WheelPositionSensor_FBMappin: component=System_Software_Architecture.AutomaticSeatadjustement.WheelPosSensor, ecu-instance=WheelPositionSensor
          LED_ASAL_FBMapping: component=System_Software_Architecture.LED_ASA, ecu-instance=LED_ASAL
          Car_Locking_System_FBMapping: component=System_Software_Architecture.Car_locking_system, ecu-instance=Car_Locking_System
          LED_PW_DN_FBMapping: component=System_Software_Architecture.LED_PW_down, ecu-instance=LED_PW_DN
          Wiper_Function_But_FBMapping: component=System_Software_Architecture.Wip_Function_Panel, ecu-instance=Wiper_Function_But
          SeatHeightSensor_FBMapping: component=System_Software_Architecture.AutomaticSeatadjustement.SeatHeigthSensor, ecu-instance=SeatHeightSensor
          Wiper_Speed_But_FBMapping: component=System_Software_Architecture.Wip_Speed_Panel, ecu-instance=Wiper_Speed_But
          PW_Position_Sensor_FBMapping: component=System_Software_Architecture.PW_pos_Sensor, ecu-instance=PW_Position_Sensor
          LED_Clean_FBMapping: component=System_Software_Architecture.LEDClean, ecu-instance=LED_Clean
          LED_EM_Heating_FBMapping: component=System_Software_Architecture.LED_Heating, ecu-instance=LED_EM_Heating
          LED_EML_FBMapping: component=System_Software_Architecture.LED_EM_Left, ecu-instance=LED_EML
          Alarm_System_Control_FBMappi: component=System_Software_Architecture.Alarm_System_Control, ecu-instance=Alarm_System_Control
          WindowHeater_FBMapping: component=System_Software_Architecture.WindowHeaterSystem.WindowHeater, ecu-instance=WindowHeater
          HighBeamSwitch_FBMapping: component=System_Software_Architecture.HighBeamSwitch, ecu-instance=HighBeamSwitch
          EM_Button_FBMapping: component=System_Software_Architecture.EM_Button, ecu-instance=EM_Button
          LED_PW_Up_FBMapping: component=System_Software_Architecture.LED_PW_UP, ecu-instance=LED_PW_Up
          LED_Frost_FBMapping: component=System_Software_Architecture.LEDFrostProtection, ecu-instance=LED_Frost
          Thermoeter_FBMapping: component=System_Software_Architecture.Thermometer, ecu-instance=Thermoeter
          LED_ASAD_FBMapping: component=System_Software_Architecture.LED_ASAD, ecu-instance=LED_ASAD
          HeadLightSwitch_FBMapping: component=System_Software_Architecture.HeadLightSwitch, ecu-instance=HeadLightSwitch
    software composition System_Software_Architecture: software-composition=System_Software_Architecture
package /Software_Types  # Software Types
package /Software_Types/Interface_Types  # Interface Types
package /Software_Types/Interface_Types/Sender__Receiver_Interfaces  # Sender-/Receiver Interfaces
package /Software_Types/Interface_Types/Sender__Receiver_Interfaces/BCS_AutomaticHeadLights/signal_internal
  8 x sender receiver interface:
    not_dark
    dark
    turn_HL_auto
    turn_HL_off
    turn_HL_on
    turn_HB_auto
    turn_HB_on
    turn_HB_off
package /Software_Types/Interface_Types/Sender__Receiver_Interfaces/BCS_AutomaticHeadLights/signal_output
  8 x sender receiver interface:
    HB_off
    HB_on
    LB_off
    LB_on
    DRL_off
    DRL_on
    PL_off
    PL_on
package /Software_Types/Interface_Types/Sender__Receiver_Interfaces/BCS_AutomaticHeadLights/signal_input
  11 x sender receiver interface:
    no_AV_detected
    AV_detected
    LightingCondition
    car_motor_off
    car_motor_on
    HL_auto_but
    HL_off_but
    HL_on_but
    HB_on_but
    HB_auto_but
    HB_off_but
package /Software_Types/Interface_Types/Sender__Receiver_Interfaces/BCS_HeatableWindows/signal_output
  4 x sender receiver interface:
    LED_HW_off
    LED_HW_on
    WH_off
    WH_on
package /Software_Types/Interface_Types/Sender__Receiver_Interfaces/BCS_WindowTemperatur/signal_internal
  sender receiver interface noFrost
  sender receiver interface frost
package /Software_Types/Interface_Types/Sender__Receiver_Interfaces/BCS_WindowTemperatur/signal_input
  sender receiver interface windShieldTemperature
package /Software_Types/Interface_Types/Sender__Receiver_Interfaces/BCS_SeatAdjustement/signal_internal
  sender receiver interface rckc_keyId
package /Software_Types/Interface_Types/Sender__Receiver_Interfaces/BCS_SeatAdjustement/signal_output
  10 x sender receiver interface:
    mv_wheel_forward
    mv_wheel_backward
    mv_wheel_down
    mv_wheel_up
    mv_seat_backward
    mv_seat_forward
    mv_seat_down
    mv_seat_up
    mv_backrest_down
    mv_backrest_up
package /Software_Types/Interface_Types/Sender__Receiver_Interfaces/BCS_SeatAdjustement/signal_input
  5 x sender receiver interface:
    rck_keyId
    wheel_pos
    seat_forward_pos
    seatHeight
    backrestPos
package /Software_Types/Interface_Types/Sender__Receiver_Interfaces/BCS_Wiper/signal_output
  10 x sender receiver interface:
    wipe_clean
    wipe_fast_speed
    wipe_medium_speed
    wipe_slow_speed
    ledWiper_off
    ledWiper_on
    ledFrostProtection_off
    ledFrostProtection_on
    ledClean_off
    ledClean_on
package /Software_Types/Interface_Types/Sender__Receiver_Interfaces/BCS_Wiper/signal_internal
  15 x sender receiver interface:
    useScreenWash
    screenWashRefilled
    screenWashLow
    rainSensor_WipeFast
    rainSensor_WipeSlow
    rainSensor_WiperOff
    clean_screen
    wip_func_auto_but
    wip_func_perm_but
    wip_func_disable_but
    wip_func_enable_but
    wip_func_clean_but
    wip_speed_l3_but
    wip_speed_l2_but
    wip_speed_l1_but
package /Software_Types/Interface_Types/Sender__Receiver_Interfaces/BCS_Wiper/signal_input
  13 x sender receiver interface:
    heavyRain_detected
    littleRain_detected
    rainDetected
    noRain_detected
    screenWashFill
    wip_auto_but
    wip_clean_but
    wip_perm_but
    wip_disable_but
    wip_enable_but
    wip_l3_but
    wip_l2_but
    wip_l1_but
package /Software_Types/Interface_Types/Sender__Receiver_Interfaces/BCS_Basic/signal_output
  34 x sender receiver interface:
    led_pw_up_on
    led_pw_up_off
    led_pw_dn_on
    led_pw_dn_off
    led_pw_cls_up_on
    led_pw_cls_up_off
    led_fp_on
    led_fp_off
    led_em_top_on
    led_em_top_off
    led_em_right_on
    led_em_right_off
    led_em_left_on
    led_em_left_off
    led_em_heating_on
    led_em_heating_off
    led_em_bottom_on
    led_em_bottom_off
    led_cls_on
    led_cls_off
    led_as_im_alarm_on
    led_as_im_alarm_off
    led_as_alarm_on
    led_as_alarm_off
    led_as_alarm_detected_on
    led_as_alarm_detected_off
    led_as_active_on
    led_as_active_off
    em_mv_up
    em_mv_right
    em_mv_left
    em_mv_down
    car_unlock
    car_lock
package /Software_Types/Interface_Types/Sender__Receiver_Interfaces/BCS_Basic/signal_input
  32 x sender receiver interface:
    time_rck_sf_elapsed
    time_heating_elapsed
    time_alarm_elapsed
    release_pw_but_up
    release_pw_but_dn
    rck_but_unlock
    rck_but_lock
    pw_rm_up
    pw_rm_dn
    pw_pos_up
    pw_pos_dn
    pw_but_mv_up
    pw_but_mv_dn
    key_pos_unlock
    key_pos_lock
    im_alarm_detected
    finger_detected
    em_too_cold
    em_pos_top
    em_pos_right
    em_pos_left
    em_pos_bottom
    em_but_mv_up
    em_but_mv_right
    em_but_mv_left
    em_but_mv_dn
    door_open
    deactivate_as
    confirm_alarm
    car_drives
    as_alarm_detected
    activate_as
package /Software_Types/Interface_Types/Sender__Receiver_Interfaces/BCS_Basic/signal_internal
  36 x sender receiver interface:
    release_pw_but
    rck_unlock
    rck_lock
      data rck_lock
    pw_mv_up
    pw_mv_dn
    pw_but_up
    pw_but_dn
    pw_auto_mv_up
    pw_auto_mv_stop
    pw_auto_mv_dn
    heating_on
    heating_off
    fp_on
    fp_off
    em_pos_vert_top
    em_pos_vert_pend
    em_pos_vert_bottom
    em_pos_hor_right
    em_pos_hor_pend
    em_pos_hor_left
    em_but_up
    em_but_right
    em_but_left
    em_but_down
    cls_unlock
    cls_lock
    as_im_alarm_on
    as_im_alarm_off
    as_deactivated
    as_alarm_was_detected
    as_alarm_was_confirmed
    as_alarm_on
    as_alarm_off
    as_active_on
    as_active_off
    as_activated
package /Software_Types/Block_Types  # Block Types
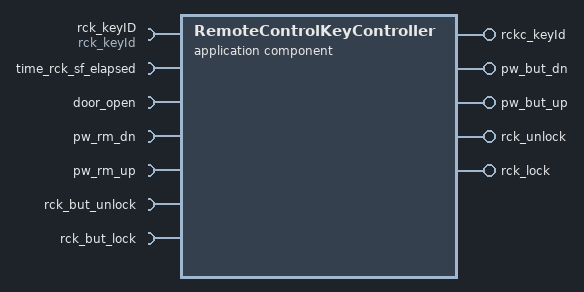
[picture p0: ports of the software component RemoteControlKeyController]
  application software component type RemoteControlKeyController
    7 x require port:
      rck_keyID: required-interface=rck_keyId
      time_rck_sf_elapsed: required-interface=time_rck_sf_elapsed
      door_open: required-interface=door_open
      pw_rm_dn: required-interface=pw_rm_dn
      pw_rm_up: required-interface=pw_rm_up
      rck_but_unlock: required-interface=rck_but_unlock
      rck_but_lock: required-interface=rck_but_lock
    5 x provide port:
      rckc_keyId: provided-interface=rckc_keyId
      pw_but_dn: provided-interface=pw_but_dn
      pw_but_up: provided-interface=pw_but_up
      rck_unlock: provided-interface=rck_unlock
      rck_lock: provided-interface=rck_lock
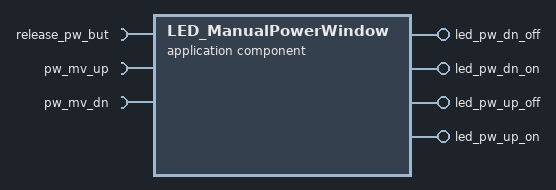
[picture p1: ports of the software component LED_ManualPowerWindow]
  application software component type LED_ManualPowerWindow
    require port release_pw_but: required-interface=release_pw_but
    require port pw_mv_up: required-interface=pw_mv_up
    require port pw_mv_dn: required-interface=pw_mv_dn
    4 x provide port:
      led_pw_dn_off: provided-interface=led_pw_dn_off
      led_pw_dn_on: provided-interface=led_pw_dn_on
      led_pw_up_off: provided-interface=led_pw_up_off
      led_pw_up_on: provided-interface=led_pw_up_on
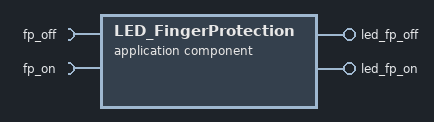
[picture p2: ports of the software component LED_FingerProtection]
  application software component type LED_FingerProtection
    require port fp_off: required-interface=fp_off
    require port fp_on: required-interface=fp_on
    provide port led_fp_off: provided-interface=led_fp_off
    provide port led_fp_on: provided-interface=led_fp_on
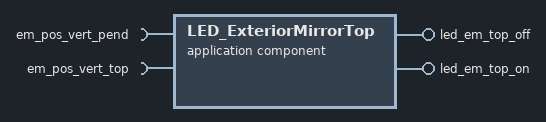
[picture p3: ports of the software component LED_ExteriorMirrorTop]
  application software component type LED_ExteriorMirrorTop
    require port em_pos_vert_pend: required-interface=em_pos_vert_pend
    require port em_pos_vert_top: required-interface=em_pos_vert_top
    provide port led_em_top_off: provided-interface=led_em_top_off
    provide port led_em_top_on: provided-interface=led_em_top_on
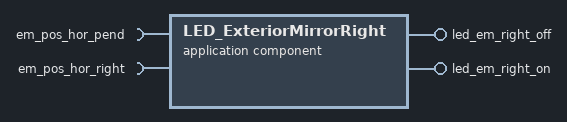
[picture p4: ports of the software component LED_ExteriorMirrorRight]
  application software component type LED_ExteriorMirrorRight
    require port em_pos_hor_pend: required-interface=em_pos_hor_pend
    require port em_pos_hor_right: required-interface=em_pos_hor_right
    provide port led_em_right_off: provided-interface=led_em_right_off
    provide port led_em_right_on: provided-interface=led_em_right_on
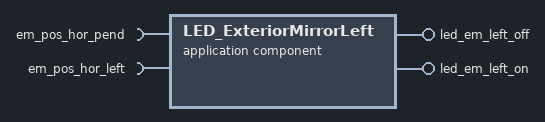
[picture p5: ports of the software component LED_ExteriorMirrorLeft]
  application software component type LED_ExteriorMirrorLeft
    require port em_pos_hor_pend: required-interface=em_pos_hor_pend
    require port em_pos_hor_left: required-interface=em_pos_hor_left
    provide port led_em_left_off: provided-interface=led_em_left_off
    provide port led_em_left_on: provided-interface=led_em_left_on
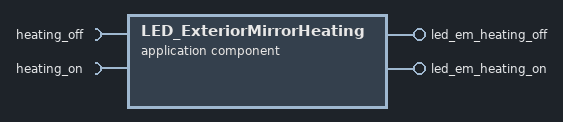
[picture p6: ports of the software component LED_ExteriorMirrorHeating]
  application software component type LED_ExteriorMirrorHeating
    require port heating_off: required-interface=heating_off
    require port heating_on: required-interface=heating_on
    provide port led_em_heating_off: provided-interface=led_em_heating_off
    provide port led_em_heating_on: provided-interface=led_em_heating_on
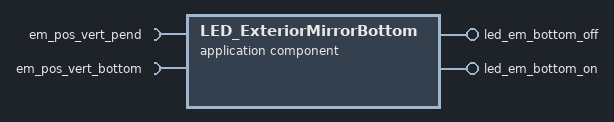
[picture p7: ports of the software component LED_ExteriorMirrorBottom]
  application software component type LED_ExteriorMirrorBottom
    require port em_pos_vert_pend: required-interface=em_pos_vert_pend
    require port em_pos_vert_bottom: required-interface=em_pos_vert_bottom
    provide port led_em_bottom_off: provided-interface=led_em_bottom_off
    provide port led_em_bottom_on: provided-interface=led_em_bottom_on
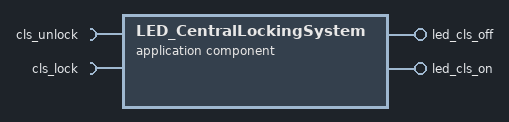
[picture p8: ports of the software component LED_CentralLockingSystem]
  application software component type LED_CentralLockingSystem
    require port cls_unlock: required-interface=cls_unlock
    require port cls_lock: required-interface=cls_lock
    provide port led_cls_off: provided-interface=led_cls_off
    provide port led_cls_on: provided-interface=led_cls_on
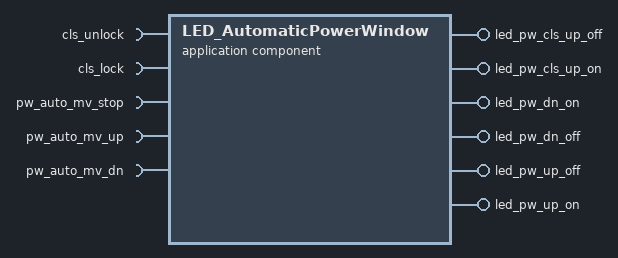
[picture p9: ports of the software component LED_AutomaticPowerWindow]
  application software component type LED_AutomaticPowerWindow
    5 x require port:
      cls_unlock: required-interface=cls_unlock
      cls_lock: required-interface=cls_lock
      pw_auto_mv_stop: required-interface=pw_auto_mv_stop
      pw_auto_mv_up: required-interface=pw_auto_mv_up
      pw_auto_mv_dn: required-interface=pw_auto_mv_dn
    6 x provide port:
      led_pw_cls_up_off: provided-interface=led_pw_cls_up_off
      led_pw_cls_up_on: provided-interface=led_pw_cls_up_on
      led_pw_dn_on: provided-interface=led_pw_dn_on
      led_pw_dn_off: provided-interface=led_pw_dn_off
      led_pw_up_off: provided-interface=led_pw_up_off
      led_pw_up_on: provided-interface=led_pw_up_on
  application software component type LED_AlarmSystemInteriorMonit  # LED_AlarmSystemInteriorMonitoring
    require port as_im_alarm_off: required-interface=as_im_alarm_off
    require port as_im_alarm_on: required-interface=as_im_alarm_on
    provide port led_as_im_alarm_off: provided-interface=led_as_im_alarm_off
    provide port led_as_im_alarm_on: provided-interface=led_as_im_alarm_on
  application software component type LED_AlarmSystemAlarmDetected
    require port as_alarm_was_confirmed: required-interface=as_alarm_was_confirmed
    require port as_alarm_was_detected: required-interface=as_alarm_was_detected
    provide port led_as_alarm_detected_off: provided-interface=led_as_alarm_detected_off
    provide port led_as_alarm_detected_on: provided-interface=led_as_alarm_detected_on
  application software component type LED_AlarmSystemAlarm
    require port as_alarm_off: required-interface=as_alarm_off
    require port as_alarm_on: required-interface=as_alarm_on
    provide port led_as_alarm_off: provided-interface=led_as_alarm_off
    provide port led_as_alarm_on: provided-interface=led_as_alarm_on
  application software component type LED_AlaramSystemActive
    require port as_active_off: required-interface=as_active_off
    require port as_active_on: required-interface=as_active_on
    provide port led_as_active_off: provided-interface=led_as_active_off
    provide port led_as_active_on: provided-interface=led_as_active_on
  application software component type HumanMachineInterface
    25 x require port:
      HL_auto_but: required-interface=HL_auto_but
      HL_on_but: required-interface=HL_off_but
      HL_off_but: required-interface=HL_on_but
      HB_auto_but: required-interface=HB_auto_but
      HB_on_but: required-interface=HB_on_but
      HB_off_but: required-interface=HB_off_but
      wip_auto_but: required-interface=wip_auto_but
      wip_l{1..3}_but: required-interface=wip_l{1..3}_but
      wip_enable_but: required-interface=wip_enable_but
      wip_disable_but: required-interface=wip_disable_but
      wip_perm_but: required-interface=wip_perm_but
      wip_clean_but: required-interface=wip_clean_but
      release_pw_but_up: required-interface=release_pw_but_up
      release_pw_but_dn: required-interface=release_pw_but_dn
      confirm_alarm: required-interface=confirm_alarm
      deactivate_as: required-interface=deactivate_as
      activate_as: required-interface=activate_as
      em_but_mv_dn: required-interface=em_but_mv_dn
      em_but_mv_up: required-interface=em_but_mv_up
      em_but_mv_right: required-interface=em_but_mv_right
      em_but_mv_left: required-interface=em_but_mv_left
      pw_but_mv_up: required-interface=pw_but_mv_up
      pw_but_mv_dn: required-interface=pw_but_mv_dn
    25 x provide port:
      turn_HL_auto: provided-interface=turn_HL_auto
      turn_HL_off: provided-interface=turn_HL_off
      turn_HL_on: provided-interface=turn_HL_on
      turn_HB_auto: provided-interface=turn_HB_auto
      turn_HB_off: provided-interface=turn_HB_off
      turn_HB_on: provided-interface=turn_HB_on
      wip_func_auto_but: provided-interface=wip_func_auto_but
      Sender_Portprototyp146  # Sender Portprototyp146
      wip_func_clean_but: provided-interface=wip_func_clean_but
      wip_speed_l{1..3}_but: provided-interface=wip_speed_l{1..3}_but
      wip_func_enable_but: provided-interface=wip_func_enable_but
      wip_func_perm_but: provided-interface=wip_func_perm_but
      wip_func_disable_but: provided-interface=wip_func_disable_but
      release_pw_but: provided-interface=release_pw_but
      as_alarm_was_confirmed: provided-interface=as_alarm_was_confirmed
      as_deactivated: provided-interface=as_deactivated
      as_activated: provided-interface=as_activated
      em_but_right: provided-interface=em_but_right
      em_but_left: provided-interface=em_but_left
      em_but_up: provided-interface=em_but_up
      em_but_dn: provided-interface=em_but_down
      pw_but_dn: provided-interface=pw_but_dn
      pw_but_up: provided-interface=pw_but_up
  application software component type FingerProtection
    require port pw_but_dn: required-interface=pw_but_dn
    require port finger_detected: required-interface=finger_detected
    provide port fp_off: provided-interface=fp_off
    provide port fp_on: provided-interface=fp_on
  application software component type ExteriorMirror
    10 x require port:
      time_heating_elapsed: required-interface=time_heating_elapsed
      em_too_cold: required-interface=em_too_cold
      em_pos_top: required-interface=em_pos_top
      em_pos_bottom: required-interface=em_pos_bottom
      em_pos_right: required-interface=em_pos_right
      em_pos_left: required-interface=em_pos_left
      em_but_left: required-interface=em_but_left
      em_but_up: required-interface=em_but_up
      em_but_down: required-interface=em_but_down
      em_but_right: required-interface=em_but_right
    12 x provide port:
      em_pos_hor_left: provided-interface=em_pos_hor_left
      em_pos_hor_right: provided-interface=em_pos_hor_right
      em_pos_hor_pend: provided-interface=em_pos_hor_pend
      em_pos_vert_top: provided-interface=em_pos_vert_top
      em_pos_vert_bottom: provided-interface=em_pos_vert_bottom
      em_pos_vert_pend: provided-interface=em_pos_vert_pend
      heating_on: provided-interface=heating_on
      heating_off: provided-interface=heating_off
      em_mv_down: provided-interface=em_mv_down
      em_mv_up: provided-interface=em_mv_up
      em_mv_right: provided-interface=em_mv_right
      em_mv_left: provided-interface=em_mv_left
  application software component type CentralLockingSystem
    6 x require port:
      door_open: required-interface=door_open
      car_drives: required-interface=car_drives
      rck_unlock: required-interface=rck_unlock
      rck_lock: required-interface=rck_lock
      key_pos_unlock: required-interface=key_pos_unlock
      key_pos_lock: required-interface=key_pos_lock
    4 x provide port:
      car_unlock: provided-interface=car_unlock
      car_lock: provided-interface=car_lock
      cls_unlock: provided-interface=cls_unlock
      cls_lock: provided-interface=cls_lock
  application software component type AlarmSystem
    9 x require port:
      im_alarm_detected: required-interface=im_alarm_detected
      rck_unlock: required-interface=rck_unlock
      rck_lock: required-interface=rck_lock
      as_deactivated: required-interface=as_deactivated
      as_activated: required-interface=as_activated
      time_alarm_elapsed: required-interface=time_alarm_elapsed
      as_alarm_detected: required-interface=as_alarm_detected
      key_pos_unlock: required-interface=key_pos_unlock
      key_pos_lock: required-interface=key_pos_lock
    7 x provide port:
      as_im_alarm_off: provided-interface=as_im_alarm_off
      as_im_alarm_on: provided-interface=as_im_alarm_on
      as_alarm_was_detected: provided-interface=as_alarm_was_detected
      as_alarm_on: provided-interface=as_alarm_on
      as_alarm_off: provided-interface=as_alarm_off
      as_active_off: provided-interface=as_active_off
      as_active_on: provided-interface=as_active_on
  19 x internal behavior:
    LED_AlarmSystemInteriorMonit_1
    LED_AlarmSystemAlarm_1
    LED_AlarmSystemAlarmDetected_1
    LED_AlaramSystemActive_1
    LED_CentralLockingSystem_1
    LED_FingerProtection_1
    LED_ExteriorMirrorHeating_1
    LED_ExteriorMirrorBottom_1
    LED_ExteriorMirrorRight_1
    LED_ExteriorMirrorLeft_1
    LED_ExteriorMirrorTop_1
    LED_AutomaticPowerWindow_1
    LED_ManualPowerWindow_1
    HumanMachineInterface_1
    CentralLockingSystem_1
    RemoteControlKeyController_1
    AlarmSystem_1
    FingerProtection_1
    ExteriorMirror_1
package /Software_Types/Block_Types/WiperSystem
  application software component type HL_Controller
    13 x require port:
      no_AV_detected: required-interface=no_AV_detected
      AV_detected: required-interface=AV_detected
      not_dark: required-interface=not_dark
      dark: required-interface=dark
      car_motor_off: required-interface=car_motor_off
      car_motor_on: required-interface=car_motor_on
      car_drives: required-interface=car_drives
      turn_HL_auto: required-interface=turn_HL_auto
      turn_HL_off: required-interface=turn_HL_off
      turn_HL_on: required-interface=turn_HL_on
      turn_HB_auto: required-interface=turn_HB_auto
      turn_HB_off: required-interface=turn_HB_off
      turn_HB_on: required-interface=turn_HB_on
    8 x provide port:
      HB_off: provided-interface=HB_off
      HB_on: provided-interface=HB_on
      LB_off: provided-interface=LB_off
      LB_on: provided-interface=LB_on
      DRL_off: provided-interface=DRL_off
      DRL_on: provided-interface=DRL_on
      PL_off: provided-interface=PL_off
      PL_on: provided-interface=PL_on
  application software component type LightSensorController
    require port LightingCondition: required-interface=LightingCondition
    provide port not_dark: provided-interface=not_dark
    provide port dark: provided-interface=dark
  application software component type WindowHeatableController
    require port sense_frost: required-interface=frost
    require port sense_noFrost: required-interface=noFrost
    4 x provide port:
      LED_HW_off: provided-interface=LED_HW_off
      LED_HW_on: provided-interface=LED_HW_on
      WH_off: provided-interface=WH_off
      Wh_on: provided-interface=WH_on
  application software component type SeatPositioncontroller
    5 x require port:
      wheelPos: required-interface=wheel_pos
      seatForwardPos: required-interface=seat_forward_pos
      seatHeight: required-interface=seatHeight
      backrestPos: required-interface=backrestPos
      rckc_keyID: required-interface=rckc_keyId
    10 x provide port:
      mv_wheel_down: provided-interface=mv_wheel_up
      mv_wheel_up
      mv_wheel_forward: provided-interface=mv_wheel_forward
      mv_wheel_backward: provided-interface=mv_wheel_backward
      mv_seat_backward: provided-interface=mv_seat_backward
      mv_seat_forward: provided-interface=mv_seat_forward
      mv_seat_down: provided-interface=mv_seat_down
      mv_seat_up: provided-interface=mv_seat_up
      mv_backrest_down: provided-interface=mv_backrest_down
      mv_backrest_up: provided-interface=mv_backrest_up
  application software component type ScreenWashController
    4 x require port:
      wip_func_clean_but: required-interface=wip_func_clean_but
      Receiver_Portprototyp216  # Receiver Portprototyp216
      Receiver_Portprototyp215  # Receiver Portprototyp215
      sense_screenWashFill: required-interface=screenWashFill
    provide port useScreenWash: provided-interface=clean_screen
    provide port screenWashRefilled: provided-interface=screenWashRefilled
    provide port screenWashLow: provided-interface=screenWashLow
  application software component type WindShieldTemperatureControl  # WindShieldTemperatureController
    require port sense_windShieldTemperature: required-interface=windShieldTemperature
    provide port no_frost_detected: provided-interface=noFrost
    provide port frost_detected: provided-interface=frost
  application software component type RainSensorController
    4 x require port:
      sense_heavyRainDetected: required-interface=heavyRain_detected
      sense_littleRainDetected: required-interface=littleRain_detected
      sense_rainDetected: required-interface=rainDetected
      sense_noRain: required-interface=noRain_detected
    provide port rainSensor_WiperOff: provided-interface=rainSensor_WiperOff
    provide port rainSensor_WipeFast: provided-interface=rainSensor_WipeFast
    provide port rainSensor_WipeSlow: provided-interface=rainSensor_WipeSlow
  application software component type WiperController
    15 x require port:
      screenWashRefilled: required-interface=screenWashRefilled
      screenWashLow: required-interface=screenWashLow
      rainSensor_WipeFast: required-interface=rainSensor_WipeFast
      rainSensor_WipeSlow: required-interface=rainSensor_WipeSlow
      rainSensor_WiperOff: required-interface=rainSensor_WiperOff
      useScreenWash_1: required-interface=clean_screen
      wip_func_auto_but: required-interface=wip_func_auto_but
      wip_func_perm_but: required-interface=wip_func_perm_but
      wip_func_disable_but: required-interface=wip_func_disable_but
      wip_func_enable_but: required-interface=wip_func_enable_but
      wip_speed_l3_but: required-interface=wip_speed_l3_but
      wip_speed_l2_but: required-interface=wip_speed_l2_but
      wip_speed_l1_but: required-interface=wip_speed_l1_but
      no_frost_detected: required-interface=noFrost
      frost_detected: required-interface=frost
    11 x provide port:
      useScreenWash: provided-interface=useScreenWash
      ledClean_off: provided-interface=ledClean_off
      ledClean_on: provided-interface=ledClean_on
      autoWiping_off: provided-interface=ledWiper_off
      autoWiping_on: provided-interface=ledWiper_on
      ledFrostProtection_off: provided-interface=ledFrostProtection_off
      ledFrostProtection_on: provided-interface=ledFrostProtection_on
      wipe_clean: provided-interface=wipe_clean
      wipe_fast_speed: provided-interface=wipe_fast_speed
      wipe_medium_speed: provided-interface=wipe_medium_speed
      wipe_slow_speed: provided-interface=wipe_slow_speed
  sensor actuator software component type HighBeam
    require port HB_off: required-interface=HB_off
    require port HB_on: required-interface=HB_on
  sensor actuator software component type LowBeam
    require port LB_off: required-interface=LB_off
    require port LB_on: required-interface=LB_on
  sensor actuator software component type DayTimeRunningLights
    require port DRL_off: required-interface=DRL_off
    require port DRL_on: required-interface=DRL_on
  sensor actuator software component type ParkingLights
    require port PL_off: required-interface=PL_off
    require port PL_on: required-interface=PL_on
  sensor actuator software component type ApproachingVehilceSensor
    provide port no_AV_detected: provided-interface=no_AV_detected
    provide port AV_detected: provided-interface=AV_detected
  sensor actuator software component type NatLightSensor
    provide port LightingCondition: provided-interface=LightingCondition
  sensor actuator software component type HeadLightSwitch
    provide port HL_auto_but: provided-interface=HL_auto_but
    provide port HL_off_but: provided-interface=HL_off_but
    provide port HL_on_but: provided-interface=HL_on_but
  sensor actuator software component type HighBeamSwitch
    provide port HB_auto_but: provided-interface=HB_auto_but
    provide port HB_on_but: provided-interface=HB_on_but
    provide port HB_off_but: provided-interface=HB_off_but
  sensor actuator software component type LED_HeatableWindow
    require port lED_HW_off: required-interface=LED_HW_off
    require port LED_HW_on: required-interface=LED_HW_on
  sensor actuator software component type WindowHeater
    require port Wh_off: required-interface=WH_off
    require port WH_on: required-interface=WH_on
  sensor actuator software component type WheelPosMotor
    4 x require port:
      mv_wheel_down: required-interface=mv_wheel_down
      mv_wheel_up: required-interface=mv_wheel_up
      mv_wheel_forward: required-interface=mv_wheel_forward
      mv_wheel_backward: required-interface=mv_wheel_backward
    provide port Sender_Portprototyp192  # Sender Portprototyp192
  sensor actuator software component type SeatForwardMotor
    require port mv_seat_backward: required-interface=mv_seat_backward
    require port mv_seat_forward: required-interface=mv_seat_forward
  sensor actuator software component type SeatHeigthMotor
    require port mv_seat_down: required-interface=mv_seat_down
    require port mv_seat_up: required-interface=mv_seat_up
  sensor actuator software component type BackrestMotor
    require port mv_backrest_down: required-interface=mv_backrest_down
    require port mv_backrest_up: required-interface=mv_backrest_up
  sensor actuator software component type WheelPossensor
    provide port wheelPos: provided-interface=wheel_pos
  sensor actuator software component type SeatForwardPosSensor
    provide port seatForwardPos: provided-interface=seat_forward_pos
  sensor actuator software component type SeatHeigthSensor
    provide port seatHeight: provided-interface=seatHeight
  sensor actuator software component type BackrestPositionSensor
    provide port backrestPos: provided-interface=backrestPos
  sensor actuator software component type ScreenWashNozzle
    require port Receiver_Portprototyp203  # Receiver Portprototyp203
    require port useScreenWash: required-interface=useScreenWash
  sensor actuator software component type HighQualityWiper
    4 x require port:
      wipe_fast: required-interface=wipe_fast_speed
      wipe_medium: required-interface=wipe_medium_speed
      wipe_slow: required-interface=wipe_slow_speed
      wipe_clean: required-interface=wipe_clean
  sensor actuator software component type LowQualityWiper
    require port Receiver_Portprototyp193  # Receiver Portprototyp193
    require port wipe_slow: required-interface=wipe_slow_speed
    require port wipe_clean: required-interface=wipe_clean
  sensor actuator software component type HighQualityRainSensor
    provide port sense_heavyRainDetected: provided-interface=heavyRain_detected
    provide port sense_littleRainDetected: provided-interface=littleRain_detected
    provide port sense_noRain: provided-interface=noRain_detected
  sensor actuator software component type LowQualityRainSensor
    provide port sense_rainDetected: provided-interface=rainDetected
    provide port sense_noRain: provided-interface=noRain_detected
  sensor actuator software component type ScreenWashSensor
    provide port sense_screenWashFill: provided-interface=screenWashFill
  sensor actuator software component type WindShieldtemperatureSensor
    provide port sense_windShieldTemperature: provided-interface=windShieldTemperature
  sensor actuator software component type LEDFrostProtection
    require port ledFrostProtection_off: required-interface=ledFrostProtection_off
    require port ledFrostProtection_on: required-interface=ledFrostProtection_on
  sensor actuator software component type LEDClean
    require port ledClean_off: required-interface=ledClean_off
    require port ledClean_on: required-interface=ledClean_on
  sensor actuator software component type LEDWiper
    require port ledWiper_off: required-interface=ledWiper_off
    require port ledWiper_on: required-interface=ledWiper_on
  sensor actuator software component type Wip_Speed_Panel
    provide port wip_l3_but: provided-interface=wip_l3_but
    provide port wip_l2_but: provided-interface=wip_l2_but
    provide port wip_l1_but: provided-interface=wip_l1_but
  sensor actuator software component type Wip_Function_Panel
    5 x provide port:
      wip_auto_but: provided-interface=wip_auto_but
      wip_clean_but: provided-interface=wip_clean_but
      wip_perm_but: provided-interface=wip_perm_but
      wip_disable_but: provided-interface=wip_disable_but
      wip_enable_but: provided-interface=wip_enable_but
  8 x internal behavior:
    HL_Controller_1
    LightSensorController_1
    WindowHeatableController_1
    WindShieldTemperatureControl_1
    SeatPositioncontroller_1
    ScreenWashController_1
    RainSensorController_1
    WiperController_1
package /Software_Types/Block_Types/PowerWindow_PW_  # PowerWindow(PW)
  application software component type AutoPW
    8 x require port:
      AutoPW_fp_off: required-interface=fp_off
      AutoPW_fp_on: required-interface=fp_on
      AutoPW_pw_pos_dn: required-interface=pw_but_dn
      AutoPW_pw_pos_up: required-interface=pw_but_up
      AutoPW_pw_but_dn: required-interface=pw_pos_dn
      AutpPW_pw_but_up: required-interface=pw_pos_up
      AutoPW_cls_lock: required-interface=cls_lock
      AUtoPW_cls_unlock: required-interface=cls_unlock
    provide port pw_auto_mv_stop: provided-interface=pw_auto_mv_stop
    provide port pw_auto_mv_up: provided-interface=pw_auto_mv_up
    provide port pw_auto_mv_dn: provided-interface=pw_auto_mv_dn
  internal behavior AutoPW_1
package /Software_Types/Block_Types/Sensor_Types  # Sensor Types
  sensor actuator software component type PW_Remote_Control
    provide port pw_but_down: provided-interface=pw_rm_dn
    provide port pw_but_up: provided-interface=pw_rm_up
  sensor actuator software component type Remote_Cotroll_Key
    4 x provide port:
      rck_keyId: provided-interface=rck_keyId
      rck_timer: provided-interface=time_rck_sf_elapsed
      rck_but_unlock: provided-interface=rck_but_unlock
      rck_but_lock: provided-interface=rck_but_lock
  sensor actuator software component type PW_Button_DN
    provide port pw_but_released: provided-interface=release_pw_but_dn
    provide port pw_but_pressed: provided-interface=pw_but_mv_dn
  sensor actuator software component type PW_Button_UP
    provide port pw_but_released: provided-interface=release_pw_but_up
    provide port pw_but_pressed: provided-interface=pw_but_mv_up
  sensor actuator software component type Alarm_System_Control
    provide port confirm_alarm: provided-interface=confirm_alarm
    provide port deactivate_as: provided-interface=deactivate_as
    provide port activate_as: provided-interface=activate_as
  sensor actuator software component type EM_Button
    4 x provide port:
      em_but_mv_dn: provided-interface=em_but_mv_dn
      em_but_mv_up: provided-interface=em_but_mv_up
      em_but_mv_right: provided-interface=em_but_mv_right
      em_but_mv_left: provided-interface=em_but_mv_left
  sensor actuator software component type Alarm_Sensor
    provide port im_alarm_detected: provided-interface=im_alarm_detected
    provide port alarm_detected: provided-interface=as_alarm_detected
    provide port alarm_time_elapsed: provided-interface=time_alarm_elapsed
  sensor actuator software component type Heating_timer
    provide port heating_time_elapsed: provided-interface=time_heating_elapsed
  sensor actuator software component type Thermometer
    provide port em_too_cold: provided-interface=em_too_cold
  sensor actuator software component type EM_Pos_Sensor
    4 x provide port:
      em_pos_top: provided-interface=em_pos_top
      em_pos_bottom: provided-interface=em_pos_bottom
      em_pos_right: provided-interface=em_pos_right
      em_pos_left: provided-interface=em_pos_left
  sensor actuator software component type Finger_Sensor_SWA
    provide port finger_detected: provided-interface=finger_detected
  sensor actuator software component type PW_pos_Sensor
    provide port pw_pos_dn: provided-interface=pw_pos_dn
    provide port pw_pos_up: provided-interface=pw_pos_up
  sensor actuator software component type door_sensor
    provide port door_open: provided-interface=door_open
  sensor actuator software component type driving_sensor
    provide port car_motor_off: provided-interface=car_motor_off
    provide port car_motor_on: provided-interface=car_motor_on
    provide port car_drives: provided-interface=car_drives
  sensor actuator software component type Key_Pos_Sensor
    provide port key_pos_unlock: provided-interface=key_pos_unlock
    provide port key_pos_lock: provided-interface=key_pos_lock
package /Software_Types/Block_Types/Actuator_Types  # Actuator Types
  sensor actuator software component type LED_ASIM
    require port led_off: required-interface=led_as_im_alarm_off
    require port led_on: required-interface=led_as_im_alarm_on
  sensor actuator software component type LED_ASAC
    require port led_off: required-interface=led_as_active_off
    require port led_on: required-interface=led_as_active_on
  sensor actuator software component type LED_ASA
    require port led_off: required-interface=led_as_alarm_off
    require port led_on: required-interface=led_as_alarm_on
  sensor actuator software component type LED_ASAD
    require port led_off: required-interface=led_as_alarm_detected_off
    require port led_on: required-interface=led_as_alarm_detected_on
  sensor actuator software component type LED_PW_CLS_UP
    require port led_off: required-interface=led_pw_cls_up_off
    require port led_on: required-interface=led_pw_cls_up_on
  sensor actuator software component type LED_PW_down
    require port led_off: required-interface=led_pw_dn_off
    require port led_on: required-interface=led_pw_dn_on
  sensor actuator software component type LED_PW_UP
    require port led_off: required-interface=led_pw_up_off
    require port led_on: required-interface=led_pw_up_on
  sensor actuator software component type LED_Heating
    require port led_off: required-interface=led_em_heating_off
    require port led_on: required-interface=led_em_heating_on
  sensor actuator software component type LED_EM_Left
    require port led_off: required-interface=led_em_left_off
    require port led_on: required-interface=led_em_left_on
  sensor actuator software component type LED_EM_Right
    require port led_off: required-interface=led_em_right_off
    require port led_on: required-interface=led_em_right_on
  sensor actuator software component type LED_EM_Top
    require port led_off: required-interface=led_em_top_off
    require port led_on: required-interface=led_em_top_on
  sensor actuator software component type LED_EM_Bottom
    require port led_off: required-interface=led_em_bottom_off
    require port led_on: required-interface=led_em_bottom_on
  sensor actuator software component type EM_Motor
    4 x require port:
      em_mv_down: required-interface=em_mv_down
      em_mv_up: required-interface=em_mv_up
      em_mv_right: required-interface=em_mv_right
      em_mv_left: required-interface=em_mv_left
  sensor actuator software component type LED_FP
    require port led_fp_off: required-interface=led_fp_off
    require port led_fp_on: required-interface=led_fp_on
  sensor actuator software component type Car_locking_system
    require port car_unlock: required-interface=car_unlock
    require port car_lock: required-interface=car_lock
  sensor actuator software component type CLS_LED
    require port led_cls_off: required-interface=led_cls_off
    require port led_cls_on: required-interface=led_cls_on
package /Data_Types  # Data Types
package /Components/Components/Komponentendiagramm/BCS_AutomaticHeadLights
  9 x ecu instance, all with com-configuration-id=0, com-processing-period=0.001, com-processing-period-gw=0.0, com-processing-period-rx=0.0, diagnostic-address=0, pdu-r-configuration-id=0, sleep-mode-supported=false, wake-up-over-bus-supported=false:
    HL_Controller
    HighBeam: category=Actuator
    LowBeam: category=Actuator
    DaytimeRunningLights: category=Actuator
    ParkingLights: category=Actuator
    ApproachingVehicle_snesor: category=Sensor
    NatLight_sensor: category=Sensor
    HeadLightSwitch: category=Sensor
    HighBeamSwitch: category=Sensor
package /Components/Components/Komponentendiagramm/BCS_HeatableWindow
  ecu instance WindowHeatableController: com-configuration-id=0, com-processing-period=0.001, com-processing-period-gw=0.0, com-processing-period-rx=0.0, diagnostic-address=0, pdu-r-configuration-id=0, sleep-mode-supported=false, wake-up-over-bus-supported=false
  ecu instance LED_HeatableWindow: category=Actuator, com-configuration-id=0, com-processing-period=0.001, com-processing-period-gw=0.0, com-processing-period-rx=0.0, diagnostic-address=0, pdu-r-configuration-id=0, sleep-mode-supported=false, wake-up-over-bus-supported=false
  ecu instance WindowHeater: category=Actuator, com-configuration-id=0, com-processing-period=0.001, com-processing-period-gw=0.0, com-processing-period-rx=0.0, diagnostic-address=0, pdu-r-configuration-id=0, sleep-mode-supported=false, wake-up-over-bus-supported=false
package /Components/Components/Komponentendiagramm/BCS_WindowTemperatureControl  # BCS_WindowTemperatureControllSystem
  ecu instance WindowTemperatureController: com-configuration-id=0, com-processing-period=0.001, com-processing-period-gw=0.0, com-processing-period-rx=0.0, diagnostic-address=0, pdu-r-configuration-id=0, sleep-mode-supported=false, wake-up-over-bus-supported=false
  ecu instance WindShieldTemperatureSensor: category=Sensor, com-configuration-id=0, com-processing-period=0.001, com-processing-period-gw=0.0, com-processing-period-rx=0.0, diagnostic-address=0, pdu-r-configuration-id=0, sleep-mode-supported=false, wake-up-over-bus-supported=false
package /Components/Components/Komponentendiagramm/BCS_SeatAdjustement
  9 x ecu instance, all with com-configuration-id=0, com-processing-period=0.001, com-processing-period-gw=0.0, com-processing-period-rx=0.0, diagnostic-address=0, pdu-r-configuration-id=0, sleep-mode-supported=false, wake-up-over-bus-supported=false:
    SeatAdjustement
    WheelPosMotor: category=Actuator
    SeatForwardMotor: category=Actuator
    SeatHeightMotor: category=Actuator
    BackrestMotor: category=Actuator
    WheelPositionSensor: category=Sensor
    SeatForwardSensor: category=Sensor
    SeatHeightSensor: category=Sensor
    BackrestPositionSensor: category=Sensor
package /Components/Components/Komponentendiagramm/BCS_Wiper
  10 x ecu instance, all with com-configuration-id=0, com-processing-period=0.001, com-processing-period-gw=0.0, com-processing-period-rx=0.0, diagnostic-address=0, pdu-r-configuration-id=0, sleep-mode-supported=false, wake-up-over-bus-supported=false:
    ECU5_Wiper
    ScreenWashNozzle: category=Actuator
    LowQualityWiper: category=Actuator
    LED_Wiper: category=Actuator
    LED_Clean: category=Actuator
    Wiper_Speed_But: category=Sensor
    Wiper_Function_But: category=Sensor
    ScreenWashSensor: category=Sensor
    LowQualityRainSensor: category=Sensor
    HighQualityRainSensor: category=Sensor
package /Components/Components/Komponentendiagramm/BCS_Basic
  37 x ecu instance, all with com-configuration-id=0, com-processing-period=0.001, com-processing-period-gw=0.0, com-processing-period-rx=0.0, diagnostic-address=0, pdu-r-configuration-id=0, sleep-mode-supported=false, wake-up-over-bus-supported=false:
    ECU2_HMI
      communication connector HMI_Inputbus_LED: nm-address=0
      communication connector HMI_Bus_Connector: nm-address=0
    ECU1_Doorsystem
      communication connector Doorsystem_Outputbus: nm-address=0
      communication connector Doorsystem_Input_Bus_Connect: nm-address=0  # Doorsystem_Input_Bus_Connector
    CLS_ECU4
      communication connector CLS_ECU_Outputbus: nm-address=0
    Alarm_System_ECU3
      communication connector AlarmSystem_Outputbus_Connec: nm-address=0  # AlarmSystem_Outputbus_Connector
      communication connector AlarmSystem_Inputbus_Connect: nm-address=0  # AlarmSystem_Inputbus_Connector
    LED_PW_Up: category=Actuator
    LED_PW_DN: category=Actuator
    LED_PW_CLS: category=Actuator
    LED_Frost: category=Actuator
    LED_FP: category=Actuator
    LED_EMT: category=Actuator
    LED_EMR: category=Actuator
    LED_EML: category=Actuator
    LED_EMB: category=Actuator
    LED_EM_Heating: category=Actuator
    LED_CLS: category=Actuator
    LED_ASIM: category=Actuator
    LED_ASAL: category=Actuator
    LED_ASAD: category=Actuator
    LED_ASAC: category=Actuator
    HighQualityWiper: category=Actuator
    EM_Motor: category=Actuator
    Car_Locking_System: category=Actuator
    Thermoeter: category=Sensor
    Remote_Control_Key: category=Sensor
    RCK_PW_Buttons: category=Sensor
    PW_Position_Sensor: category=Sensor
    PW_But_UP: category=Sensor
    PW_But_DN: category=Sensor
    Key_Pos_Sensor: category=Sensor
    Heating_Timer: category=Sensor
    Finger_Sensor_HW: category=Sensor
    EM_Pos_Sensor: category=Sensor
    EM_Button: category=Sensor
    Driving_Snesor: category=Sensor
    Door_Sensor: category=Sensor
    Alarm_System_Control: category=Sensor
    Alarm_Sensor: category=Sensor
package /Implementation
  28 x swc implementation, all with sw-major-version=0, sw-minor-version=0, sw-patch-version=0, vendor-id=0:
    Impl_LED_ExteriorMirrorLeft: behavior=LED_ExteriorMirrorLeft_1
    Impl_HL_Controller: behavior=HL_Controller_1
    Impl_LED_AutomaticPowerWindo: behavior=LED_AutomaticPowerWindow_1
    Impl_LED_AlarmSystemInterior: behavior=LED_AlarmSystemInteriorMonit_1
    Impl_CentralLockingSystem: behavior=CentralLockingSystem_1
    Impl_LED_CentralLockingSyste: behavior=LED_CentralLockingSystem_1
    Impl_ScreenWashController: behavior=ScreenWashController_1
    Impl_LED_AlaramSystemActive: behavior=LED_AlaramSystemActive_1
    Impl_HumanMachineInterface: behavior=HumanMachineInterface_1
    Impl_WindowHeatableControlle: behavior=WindowHeatableController_1
    Impl_SeatPositioncontroller: behavior=SeatPositioncontroller_1
    Impl_WiperController: behavior=WiperController_1
    Impl_AlarmSystem: behavior=AlarmSystem_1
    Impl_WindShieldTemperatureCo: behavior=WindShieldTemperatureControl_1
    Impl_FingerProtection: behavior=FingerProtection_1
    Impl_RemoteControlKeyControl: behavior=RemoteControlKeyController_1
    Impl_LED_ManualPowerWindow: behavior=LED_ManualPowerWindow_1
    Impl_AutoPW: behavior=AutoPW_1
    Impl_LED_ExteriorMirrorBotto: behavior=LED_ExteriorMirrorBottom_1
    Impl_RainSensorController: behavior=RainSensorController_1
    Impl_LED_ExteriorMirrorRight: behavior=LED_ExteriorMirrorRight_1
    Impl_LED_AlarmSystemAlarmDet: behavior=LED_AlarmSystemAlarmDetected_1
    Impl_ExteriorMirror: behavior=ExteriorMirror_1
    Impl_LED_FingerProtection: behavior=LED_FingerProtection_1
    Impl_LED_ExteriorMirrorHeati: behavior=LED_ExteriorMirrorHeating_1
    Impl_LED_ExteriorMirrorTop: behavior=LED_ExteriorMirrorTop_1
    Impl_LED_AlarmSystemAlarm: behavior=LED_AlarmSystemAlarm_1
    Impl_LightSensorController: behavior=LightSensorController_1
